# APM32L08x register map
File version: 1.0
CPU: CM0+ r0p0, little endian, MPU, no FPU, 4 interrupt priority bits
Registers are 32-bit, read-write, reset 0x0 unless marked. A register's access mark holds for its fields unless they carry their own. Offsets are from the block's base; [hi:lo] are bit positions; {n}, {i} and the like mark numbered series.

## LPTMR — Low power timer
Base 0x40007C00
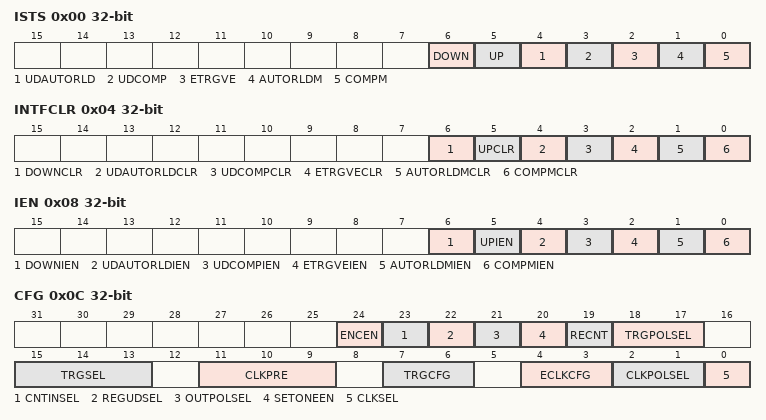
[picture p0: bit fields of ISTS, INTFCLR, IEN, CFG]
0x00 ISTS ro — Interrupt and Status Register
  [6] DOWN — Down Count Flag
  [5] UP — Up Count Flag
  [4] UDAUTORLD — Update Auto-Reload Register Flag
  [3] UDCOMP — Update Comparison Register Flag
  [2] ETRGVE — External Trigger Valid Edge Flag
  [1] AUTORLDM — Autoreload Value Match Flag
  [0] COMPM — Compare Value Match Flag
0x04 INTFCLR wo — Interrupt Clear Register
  [6] DOWNCLR — Down Count Flag Clear
  [5] UPCLR — Up Count Flag Clear
  [4] UDAUTORLDCLR — Update Auto-Reload Register Flag Clear
  [3] UDCOMPCLR — Update Comparison Register Flag Clear
  [2] ETRGVECLR — External Trigger Valid Edge Flag Clear
  [1] AUTORLDMCLR — Autoreload Value Match Flag Clear
  [0] COMPMCLR — Compare Value Match Flag Clear
0x08 IEN — Interrupt Enable Register
  [6] DOWNIEN — Down Count Interrupt Enable
  [5] UPIEN — Up Count Interrupt Enable
  [4] UDAUTORLDIEN — Update Auto-Reload Register Interrupt Enable
  [3] UDCOMPIEN — Update Comparison Register Interrupt Enable
  [2] ETRGVEIEN — External Trigger Valid Edge Interrupt Enable
  [1] AUTORLDMIEN — Autoreload Value Match Interrupt Enable
  [0] COMPMIEN — Compare Value Match Interrupt Enable
0x0C CFG — Configuration Register
  [24] ENCEN — Encoder Mode Enable
  [23] CNTINSEL — Counter Increase Mode Select
  [22] REGUDSEL — Registers Update Mode Select
  [21] OUTPOLSEL — Output Polarity Select
  [20] SETONEEN — Set-once Mode Enable
  [19] RECNT — Restart Counter
  [18:17] TRGPOLSEL — Trigger Select and Polarity
  [15:13] TRGSEL — Trigger Selector
  [11:9] CLKPRE — Clock Prescaler
  [7:6] TRGCFG — Digital Filter Trigger Configurable
  [4:3] ECLKCFG — External Clock Digital Filter Configurable
  [2:1] CLKPOLSEL — Clock Polarity Select
  [0] CLKSEL — Clock Selector
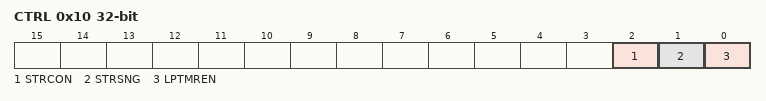
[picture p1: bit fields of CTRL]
0x10 CTRL — Control Register
  [2] STRCON — LPTMR Start in Continuous Mode
  [1] STRSNG — LPTMR Start in Single Pulse Mode
  [0] LPTMREN — LPTMR Enable
0x14 COMPV — Compare Register
  [15:0] COMPV — Compare value
0x18 AUTORLD reset 0x1 — Autoreload Register
  [15:0] AUTORLD — Auto reload value
0x1C CNT ro — Counter Register
  [15:0] CNT — Counter value

## RNG — Random number generator
Base 0x40025000
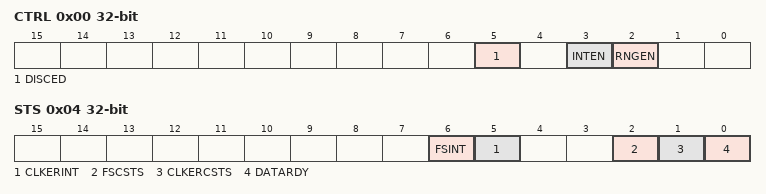
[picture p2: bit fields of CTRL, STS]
0x00 CTRL — control register
  [5] DISCED — Disable Clock Error Detection
  [3] INTEN — Interrupt Enable
  [2] RNGEN — RNG Enable
0x04 STS access per field — status register
  [6] FSINT rw — Faulty Sequence Interrupt Status
  [5] CLKERINT rw — RNGCLK Error Interrupt Status
  [2] FSCSTS ro — Faulty Sequence Current Status
  [1] CLKERCSTS ro — RNGCLK Error Current Status
  [0] DATARDY ro — Data Ready
0x08 DATA ro
  [31:0] DATA — Random Data

## PMU — Power control
Base 0x40007000
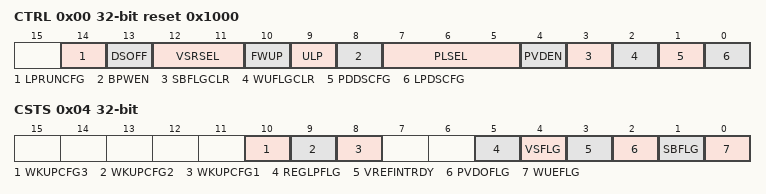
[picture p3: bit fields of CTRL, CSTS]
0x00 CTRL reset 0x1000 — power control register
  [14] LPRUNCFG — Regulator In Low Power Run Mode Configurate
  [13] DSOFF
  [12:11] VSRSEL — Voltage Scaling Range Select
  [10] FWUP — Fast Wakeup
  [9] ULP — Ultra-Low-Power Mode
  [8] BPWEN — Backup Domain Write Access Enable
  [7:5] PLSEL — PVD Level Select
  [4] PVDEN — Power Voltage Detector Enable
  [3] SBFLGCLR — Standby Flag Clear
  [2] WUFLGCLR — Wakeup Flag Clear
  [1] PDDSCFG — Pown Down Deep Sleep Configure
  [0] LPDSCFG — Low Power Deepsleep Configure
0x04 CSTS access per field — power control/status register
  [10] WKUPCFG3 rw — WKUP Pin 3 Configure
  [9] WKUPCFG2 rw — WKUP Pin 2 Configure
  [8] WKUPCFG1 rw — WKUP Pin 1 Configure
  [5] REGLPFLG ro — Regulator LP Flag
  [4] VSFLG ro — Voltage Scaling select flag
  [3] VREFINTRDY ro — VREFINT ready flag
  [2] PVDOFLG ro — PVD Output Flag
  [1] SBFLG ro — Standby Flag
  [0] WUEFLG ro — Wakeup Event Flag

## LPUART — Universal synchronous asynchronous receiver transmitter
Base 0x40004800
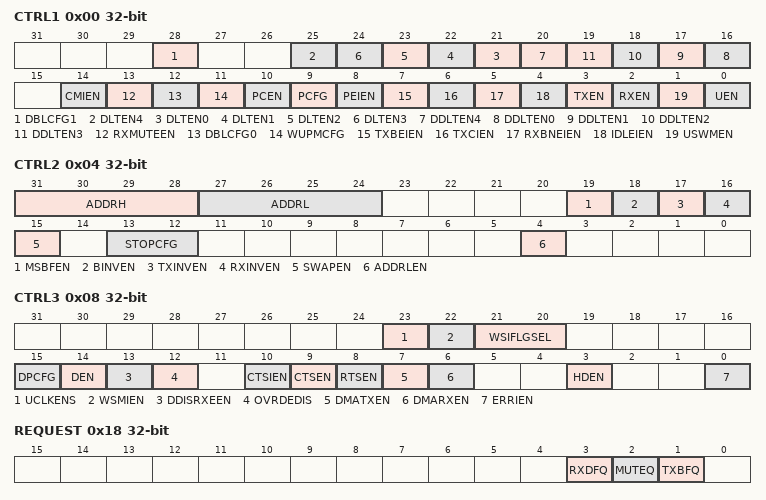
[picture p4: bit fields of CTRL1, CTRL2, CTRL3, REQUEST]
0x00 CTRL1 — Control register 1
  [28] DBLCFG1 — Data Bits Length Configure
  [25] DLTEN4 — Driver Lead Time Enable
  [n+21] DLTEN{n} (n=0..3)
  [20] DDLTEN4 — Driver De-lead Time Enable
  [n+16] DDLTEN{n} (n=0..3)
  [14] CMIEN — Character Match Interrupt Enable
  [13] RXMUTEEN — Receive Mute Mode Enable
  [12] DBLCFG0 — Data Bits Length Configure
  [11] WUPMCFG — Wakeup Method Configure
  [10] PCEN — Parity Control Enable
  [9] PCFG — Odd/Even Parity Configure
  [8] PEIEN — Parity Error Interrupt Enable
  [7] TXBEIEN — Transmit Buffer Empty Interrupt Enable
  [6] TXCIEN — Transmit Complete Interrupt Enable
  [5] RXBNEIEN — Receive Buffer Not Empty Interrupt Enable
  [4] IDLEIEN — IDLE Interrupt Enable
  [3] TXEN — Transmitte Enable
  [2] RXEN — Receive Enable
  [1] USWMEN — LPUART in Stop Mode Wake Up MCU Enable
  [0] UEN — LPUART Enable
0x04 CTRL2 — Control register 2
  [31:28] ADDRH — LPUART Device Node Address High Setup
  [27:24] ADDRL — LPUART Device Node Address Low Setup
  [19] MSBFEN — Most Significant Bit First Enable
  [18] BINVEN — Binary Data Inversion Enable
  [17] TXINVEN — TX Pin Active Level Inversion Enable
  [16] RXINVEN — RX Pin Active Level Inversion Enable
  [15] SWAPEN — Swap TX/RX Pins Function Enable
  [13:12] STOPCFG — STOP Bit Configure
  [4] ADDRLEN — Slave Address Length Configure
0x08 CTRL3 — Control register 3
  [23] UCLKENS — LPUART Clock Enable in Stop Mode
  [22] WSMIEN — Wakeup from Stop mode interrupt enable
  [21:20] WSIFLGSEL — Wakeup From Stop Mode Interrupt Flag Select
  [15] DPCFG — Driver Polarity Configure
  [14] DEN — Driver Enable
  [13] DDISRXEEN — DMA Disable on Receive Error Enable
  [12] OVRDEDIS — Overrun Detection Disable
  [10] CTSIEN — CTS Interrupt Enable
  [9] CTSEN — CTS Function Enable
  [8] RTSEN — RTS Function Enable
  [7] DMATXEN — DMA Transmit Enable
  [6] DMARXEN — DMA Receive Enable
  [3] HDEN — Half-duplex Mode Enable
  [0] ERRIEN — Error Interrupt Enable
0x0C BR — Baud rate register
  [19:0] BR — LPUART Baud Rate Divider factor
0x18 REQUEST wo
  [3] RXDFQ — Receive Data Flush Request
  [2] MUTEQ — Mute Mode Request
  [1] TXBFQ — Transmit Break Frame Request
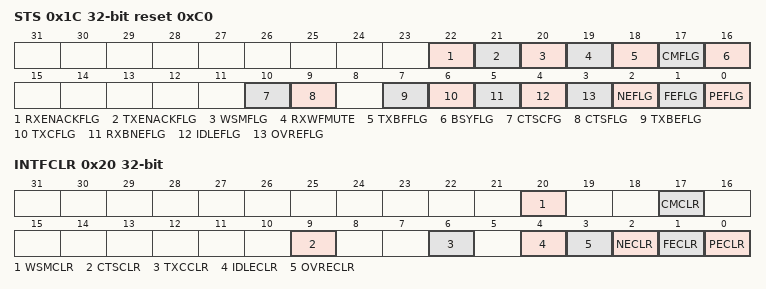
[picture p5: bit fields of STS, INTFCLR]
0x1C STS ro reset 0xC0 — Interrupt & status register
  [22] RXENACKFLG — Receive Enable Acknowledge Flag
  [21] TXENACKFLG — Transmit Enable Acknowledge Flag
  [20] WSMFLG — Wakeup From Stop Mode Flag
  [19] RXWFMUTE — Receiver Wakeup From Mute Mode
  [18] TXBFFLG — Transmit Break Frame Flag
  [17] CMFLG — Character Match Flag
  [16] BSYFLG — Busy Flag
  [10] CTSCFG — CTS Status Configure
  [9] CTSFLG — CTS Change Flag
  [7] TXBEFLG — Transmit Data Buffer Empty Flag
  [6] TXCFLG — Transmit Data Complete Flag
  [5] RXBNEFLG — Receive Data Buffer Not Empty Flag
  [4] IDLEFLG — IDLE Line Detected Flag
  [3] OVREFLG — Overrun Error Occur Flag
  [2] NEFLG — Noise Error Occur Flag
  [1] FEFLG — Frame Error Occur Flag
  [0] PEFLG — Parity Error Occur Flag
0x20 INTFCLR wo — Interrupt flag clear register
  [20] WSMCLR — Wakeup From Stop Mode Flag Clear
  [17] CMCLR — Character Match Flag Clear
  [9] CTSCLR — CTS Flag Clear
  [6] TXCCLR — Transmission Data Complete Flag Clear
  [4] IDLECLR — IDLE Line Detected Clear Flag
  [3] OVRECLR — Overrun Error Flag Clear
  [2] NECLR — Noise Detected Flag Clear
  [1] FECLR — Framing Error Flag Clear
  [0] PECLR — Parity Error Flag Clear
0x24 RXDATA ro — Receive data register
  [8:0] RXDATA — Receive Data Value Setup
0x28 TXDATA — Transmit data register
  [8:0] TXDATA — Transmit Data Value Setup

## NVIC — Nested Vectored Interrupt Controller
Base 0xE000E100
0x00 ISER — Interrupt Set Enable Register
  [31:0] SETENA
0x80 ICER — Interrupt Clear Enable Register
  [31:0] CLRENA
0x100 ISPR — Interrupt Set-Pending Register
  [31:0] SETPEND
0x180 ICPR — Interrupt Clear-Pending Register
  [31:0] CLRPEND
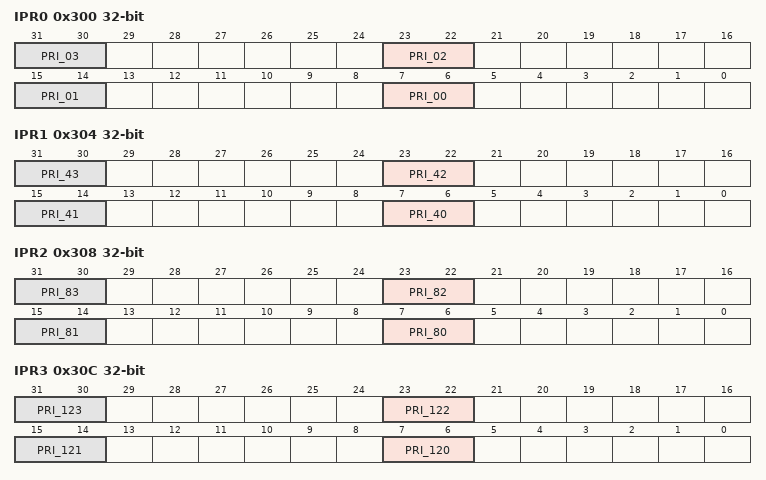
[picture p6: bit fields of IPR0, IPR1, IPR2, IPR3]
0x300 IPR0 — Interrupt Priority Register 0
  [8n+7:8n+6] PRI_{n:02} (n=0..3)
0x304 IPR1 — Interrupt Priority Register 1
  [8n-313:8n-314] PRI_{n} (n=40..43)
0x308 IPR2 — Interrupt Priority Register 2
  [8n-633:8n-634] PRI_{n} (n=80..83)
0x30C IPR3 — Interrupt Priority Register 3
  [8n-953:8n-954] PRI_{n} (n=120..123)
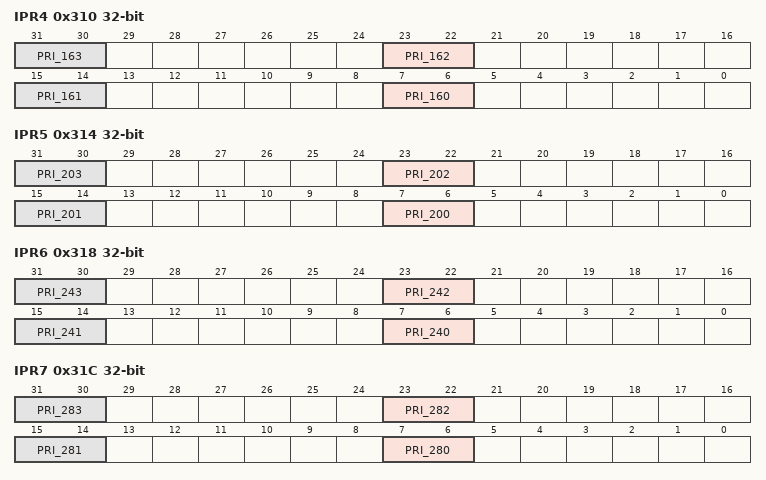
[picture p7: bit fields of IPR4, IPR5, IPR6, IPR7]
0x310 IPR4 — Interrupt Priority Register 4
  [8n-1273:8n-1274] PRI_{n} (n=160..163)
0x314 IPR5 — Interrupt Priority Register 5
  [8n-1593:8n-1594] PRI_{n} (n=200..203)
0x318 IPR6 — Interrupt Priority Register 6
  [8n-1913:8n-1914] PRI_{n} (n=240..243)
0x31C IPR7 — Interrupt Priority Register 7
  [8n-2233:8n-2234] PRI_{n} (n=280..283)
